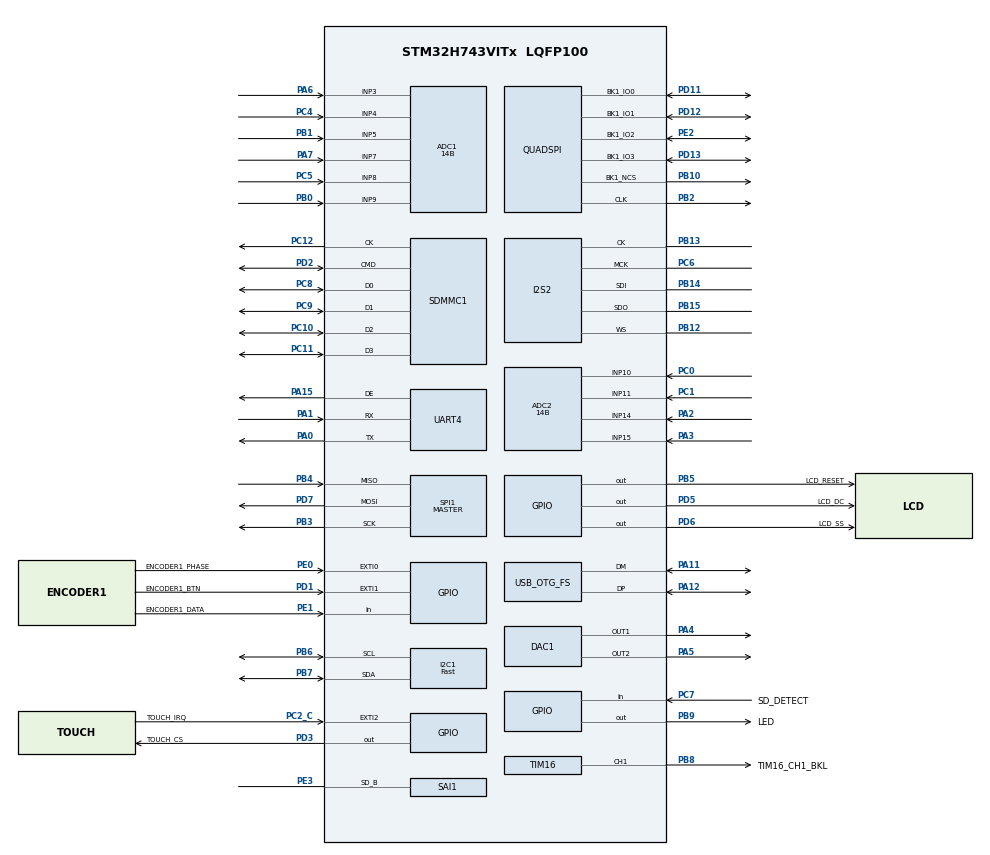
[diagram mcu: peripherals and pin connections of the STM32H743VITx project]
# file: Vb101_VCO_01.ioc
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ADC1.Channel-1\#ChannelRegularConversion=ADC_CHANNEL_3
ADC1.Channel-2\#ChannelRegularConversion=ADC_CHANNEL_4
ADC1.Channel-3\#ChannelRegularConversion=ADC_CHANNEL_5
ADC1.Channel-4\#ChannelRegularConversion=ADC_CHANNEL_7
ADC1.Channel-5\#ChannelRegularConversion=ADC_CHANNEL_8
ADC1.Channel-6\#ChannelRegularConversion=ADC_CHANNEL_9
ADC1.ContinuousConvMode=DISABLE
ADC1.ConversionDataManagement=ADC_CONVERSIONDATA_DMA_CIRCULAR
ADC1.EOCSelection=ADC_EOC_SEQ_CONV
ADC1.ExternalTrigConv=ADC_EXTERNALTRIG_T6_TRGO
ADC1.NbrOfConversion=6
ADC1.NbrOfConversionFlag=1
ADC1.OffsetNumber-1\#ChannelRegularConversion=ADC_OFFSET_NONE
ADC1.OffsetNumber-2\#ChannelRegularConversion=ADC_OFFSET_NONE
ADC1.OffsetNumber-3\#ChannelRegularConversion=ADC_OFFSET_NONE
ADC1.OffsetNumber-4\#ChannelRegularConversion=ADC_OFFSET_NONE
ADC1.OffsetNumber-5\#ChannelRegularConversion=ADC_OFFSET_NONE
ADC1.OffsetNumber-6\#ChannelRegularConversion=ADC_OFFSET_NONE
ADC1.OffsetSignedSaturation-1\#ChannelRegularConversion=DISABLE
ADC1.OffsetSignedSaturation-2\#ChannelRegularConversion=DISABLE
ADC1.OffsetSignedSaturation-3\#ChannelRegularConversion=DISABLE
ADC1.OffsetSignedSaturation-4\#ChannelRegularConversion=DISABLE
ADC1.OffsetSignedSaturation-5\#ChannelRegularConversion=DISABLE
ADC1.OffsetSignedSaturation-6\#ChannelRegularConversion=DISABLE
ADC1.OversamplingMode=ENABLE
ADC1.Rank-1\#ChannelRegularConversion=1
ADC1.Rank-2\#ChannelRegularConversion=2
ADC1.Rank-3\#ChannelRegularConversion=3
ADC1.Rank-4\#ChannelRegularConversion=4
ADC1.Rank-5\#ChannelRegularConversion=5
ADC1.Rank-6\#ChannelRegularConversion=6
ADC1.Ratio=64
ADC1.Resolution=ADC_RESOLUTION_14B
ADC1.RightBitShift=ADC_RIGHTBITSHIFT_6
ADC1.SamplingTime-1\#ChannelRegularConversion=ADC_SAMPLETIME_1CYCLE_5
ADC1.SamplingTime-2\#ChannelRegularConversion=ADC_SAMPLETIME_1CYCLE_5
ADC1.SamplingTime-3\#ChannelRegularConversion=ADC_SAMPLETIME_1CYCLE_5
ADC1.SamplingTime-4\#ChannelRegularConversion=ADC_SAMPLETIME_1CYCLE_5
ADC1.SamplingTime-5\#ChannelRegularConversion=ADC_SAMPLETIME_1CYCLE_5
ADC1.SamplingTime-6\#ChannelRegularConversion=ADC_SAMPLETIME_1CYCLE_5
ADC1.master=1
ADC2.Channel-0\#ChannelRegularConversion=ADC_CHANNEL_10
ADC2.Channel-1\#ChannelRegularConversion=ADC_CHANNEL_11
ADC2.Channel-2\#ChannelRegularConversion=ADC_CHANNEL_14
ADC2.Channel-3\#ChannelRegularConversion=ADC_CHANNEL_15
ADC2.ContinuousConvMode=DISABLE
ADC2.ConversionDataManagement=ADC_CONVERSIONDATA_DMA_CIRCULAR
ADC2.EOCSelection=ADC_EOC_SEQ_CONV
ADC2.ExternalTrigConv=ADC_EXTERNALTRIG_T6_TRGO
ADC2.NbrOfConversion=4
ADC2.NbrOfConversionFlag=1
ADC2.OffsetNumber-0\#ChannelRegularConversion=ADC_OFFSET_NONE
ADC2.OffsetNumber-1\#ChannelRegularConversion=ADC_OFFSET_NONE
ADC2.OffsetNumber-2\#ChannelRegularConversion=ADC_OFFSET_NONE
ADC2.OffsetNumber-3\#ChannelRegularConversion=ADC_OFFSET_NONE
ADC2.OffsetSignedSaturation-0\#ChannelRegularConversion=DISABLE
ADC2.OffsetSignedSaturation-1\#ChannelRegularConversion=DISABLE
ADC2.OffsetSignedSaturation-2\#ChannelRegularConversion=DISABLE
ADC2.OffsetSignedSaturation-3\#ChannelRegularConversion=DISABLE
ADC2.Rank-0\#ChannelRegularConversion=1
ADC2.Rank-1\#ChannelRegularConversion=2
ADC2.Rank-2\#ChannelRegularConversion=3
ADC2.Rank-3\#ChannelRegularConversion=4
ADC2.Resolution=ADC_RESOLUTION_14B
ADC2.SamplingTime-0\#ChannelRegularConversion=ADC_SAMPLETIME_1CYCLE_5
ADC2.SamplingTime-1\#ChannelRegularConversion=ADC_SAMPLETIME_1CYCLE_5
ADC2.SamplingTime-2\#ChannelRegularConversion=ADC_SAMPLETIME_1CYCLE_5
ADC2.SamplingTime-3\#ChannelRegularConversion=ADC_SAMPLETIME_1CYCLE_5
CORTEX_M7.AccessPermission-Cortex_Memory_Protection_Unit_Region0_Settings=MPU_REGION_FULL_ACCESS
CORTEX_M7.AccessPermission_Spec=MPU_REGION_FULL_ACCESS
CORTEX_M7.BaseAddress-Cortex_Memory_Protection_Unit_Region0_Settings=0x30000000
CORTEX_M7.BaseAddress_Spec=0x24040000
CORTEX_M7.CPU_DCache=Disabled
CORTEX_M7.CPU_ICache=Enabled
CORTEX_M7.Enable-Cortex_Memory_Protection_Unit_Region0_Settings=MPU_REGION_ENABLE
CORTEX_M7.Enable_S-Cortex_Memory_Protection_Unit_Region1_Settings_S=__NULL
CORTEX_M7.IsBufferable-Cortex_Memory_Protection_Unit_Region0_Settings=MPU_ACCESS_BUFFERABLE
CORTEX_M7.IsBufferable_Spec=MPU_ACCESS_BUFFERABLE
CORTEX_M7.IsShareable-Cortex_Memory_Protection_Unit_Region0_Settings=MPU_ACCESS_SHAREABLE
CORTEX_M7.MPU_Control=__NULL
CORTEX_M7.Size-Cortex_Memory_Protection_Unit_Region0_Settings=MPU_REGION_SIZE_4KB
CORTEX_M7.Size_Spec=MPU_REGION_SIZE_64KB
CORTEX_M7.default_mode_Activation=1
DAC1.DAC_Channel-DAC_OUT1_ExtAndInt=DAC_CHANNEL_1
DAC1.DAC_Channel-DAC_OUT2_ExtAndInt=DAC_CHANNEL_2
Dma.ADC1.0.Direction=DMA_PERIPH_TO_MEMORY
Dma.ADC1.0.EventEnable=DISABLE
Dma.ADC1.0.FIFOMode=DMA_FIFOMODE_DISABLE
Dma.ADC1.0.Instance=DMA1_Stream0
Dma.ADC1.0.MemDataAlignment=DMA_MDATAALIGN_HALFWORD
Dma.ADC1.0.MemInc=DMA_MINC_ENABLE
Dma.ADC1.0.Mode=DMA_CIRCULAR
Dma.ADC1.0.PeriphDataAlignment=DMA_PDATAALIGN_HALFWORD
Dma.ADC1.0.PeriphInc=DMA_PINC_DISABLE
Dma.ADC1.0.Polarity=HAL_DMAMUX_REQ_GEN_RISING
Dma.ADC1.0.Priority=DMA_PRIORITY_LOW
Dma.ADC1.0.RequestNumber=1
Dma.ADC1.0.SignalID=NONE
Dma.ADC1.0.SyncEnable=DISABLE
Dma.ADC1.0.SyncPolarity=HAL_DMAMUX_SYNC_NO_EVENT
Dma.ADC1.0.SyncRequestNumber=1
Dma.ADC1.0.SyncSignalID=NONE
Dma.ADC2.1.Direction=DMA_PERIPH_TO_MEMORY
Dma.ADC2.1.EventEnable=DISABLE
Dma.ADC2.1.FIFOMode=DMA_FIFOMODE_DISABLE
Dma.ADC2.1.Instance=DMA1_Stream1
Dma.ADC2.1.MemDataAlignment=DMA_MDATAALIGN_HALFWORD
Dma.ADC2.1.MemInc=DMA_MINC_ENABLE
Dma.ADC2.1.Mode=DMA_CIRCULAR
Dma.ADC2.1.PeriphDataAlignment=DMA_PDATAALIGN_HALFWORD
Dma.ADC2.1.PeriphInc=DMA_PINC_DISABLE
Dma.ADC2.1.Polarity=HAL_DMAMUX_REQ_GEN_RISING
Dma.ADC2.1.Priority=DMA_PRIORITY_LOW
Dma.ADC2.1.RequestNumber=1
Dma.ADC2.1.SignalID=NONE
Dma.ADC2.1.SyncEnable=DISABLE
Dma.ADC2.1.SyncPolarity=HAL_DMAMUX_SYNC_NO_EVENT
Dma.ADC2.1.SyncRequestNumber=1
Dma.ADC2.1.SyncSignalID=NONE
Dma.Request0=ADC1
Dma.Request1=ADC2
Dma.Request2=SPI2_TX
Dma.Request3=SPI2_RX
Dma.Request4=SPI1_TX
Dma.SPI1_TX.4.Direction=DMA_MEMORY_TO_PERIPH
Dma.SPI1_TX.4.EventEnable=DISABLE
Dma.SPI1_TX.4.FIFOMode=DMA_FIFOMODE_DISABLE
Dma.SPI1_TX.4.Instance=DMA1_Stream4
Dma.SPI1_TX.4.MemDataAlignment=DMA_MDATAALIGN_BYTE
Dma.SPI1_TX.4.MemInc=DMA_MINC_ENABLE
Dma.SPI1_TX.4.Mode=DMA_NORMAL
Dma.SPI1_TX.4.PeriphDataAlignment=DMA_PDATAALIGN_BYTE
Dma.SPI1_TX.4.PeriphInc=DMA_PINC_DISABLE
Dma.SPI1_TX.4.Polarity=HAL_DMAMUX_REQ_GEN_RISING
Dma.SPI1_TX.4.Priority=DMA_PRIORITY_LOW
Dma.SPI1_TX.4.RequestNumber=1
Dma.SPI1_TX.4.SignalID=NONE
Dma.SPI1_TX.4.SyncEnable=DISABLE
Dma.SPI1_TX.4.SyncPolarity=HAL_DMAMUX_SYNC_NO_EVENT
Dma.SPI1_TX.4.SyncRequestNumber=1
Dma.SPI1_TX.4.SyncSignalID=NONE
Dma.SPI2_RX.3.Direction=DMA_PERIPH_TO_MEMORY
Dma.SPI2_RX.3.EventEnable=DISABLE
Dma.SPI2_RX.3.FIFOMode=DMA_FIFOMODE_DISABLE
Dma.SPI2_RX.3.Instance=DMA2_Stream1
Dma.SPI2_RX.3.MemDataAlignment=DMA_MDATAALIGN_HALFWORD
Dma.SPI2_RX.3.MemInc=DMA_MINC_ENABLE
Dma.SPI2_RX.3.Mode=DMA_CIRCULAR
Dma.SPI2_RX.3.PeriphDataAlignment=DMA_PDATAALIGN_HALFWORD
Dma.SPI2_RX.3.PeriphInc=DMA_PINC_DISABLE
Dma.SPI2_RX.3.Polarity=HAL_DMAMUX_REQ_GEN_RISING
Dma.SPI2_RX.3.Priority=DMA_PRIORITY_LOW
Dma.SPI2_RX.3.RequestNumber=1
Dma.SPI2_RX.3.SignalID=NONE
Dma.SPI2_RX.3.SyncEnable=DISABLE
Dma.SPI2_RX.3.SyncPolarity=HAL_DMAMUX_SYNC_NO_EVENT
Dma.SPI2_RX.3.SyncRequestNumber=1
Dma.SPI2_RX.3.SyncSignalID=NONE
Dma.SPI2_TX.2.Direction=DMA_MEMORY_TO_PERIPH
Dma.SPI2_TX.2.EventEnable=DISABLE
Dma.SPI2_TX.2.FIFOMode=DMA_FIFOMODE_DISABLE
Dma.SPI2_TX.2.Instance=DMA2_Stream0
Dma.SPI2_TX.2.MemDataAlignment=DMA_MDATAALIGN_HALFWORD
Dma.SPI2_TX.2.MemInc=DMA_MINC_ENABLE
Dma.SPI2_TX.2.Mode=DMA_CIRCULAR
Dma.SPI2_TX.2.PeriphDataAlignment=DMA_PDATAALIGN_HALFWORD
Dma.SPI2_TX.2.PeriphInc=DMA_PINC_DISABLE
Dma.SPI2_TX.2.Polarity=HAL_DMAMUX_REQ_GEN_RISING
Dma.SPI2_TX.2.Priority=DMA_PRIORITY_LOW
Dma.SPI2_TX.2.RequestNumber=1
Dma.SPI2_TX.2.SignalID=NONE
Dma.SPI2_TX.2.SyncEnable=DISABLE
Dma.SPI2_TX.2.SyncPolarity=HAL_DMAMUX_SYNC_NO_EVENT
Dma.SPI2_TX.2.SyncRequestNumber=1
Dma.SPI2_TX.2.SyncSignalID=NONE
FATFS.BSP.number=1
FATFS._FS_EXFAT=1
FATFS._FS_TINY=1
FATFS._USE_LFN=1
FATFS0.BSP.STBoard=false
FATFS0.BSP.api=Unknown
FATFS0.BSP.instance=PC7
FATFS0.BSP.ip=GPIO
FATFS0.BSP.mode=Input
FATFS0.BSP.name=Detect_SDIO
FATFS0.BSP.solution=PC7
I2C1.I2C_Speed_Mode=I2C_Fast
I2C1.Timing=0x0010061A
I2S2.AudioFreq=I2S_AUDIOFREQ_48K
I2S2.DataFormat=I2S_DATAFORMAT_16B_EXTENDED
I2S2.ErrorAudioFreq=0.0 %
I2S2.Instance=SPI$Index
I2S2.RealAudioFreq=48.0 KHz
Mcu.Family=STM32H7
Mcu.Name=STM32H743VITx
Mcu.Package=LQFP100
NVIC.DMA1_Stream0_IRQn=true\:0\:0\:false\:false\:true\:false\:true\:true
NVIC.DMA1_Stream1_IRQn=true\:0\:0\:false\:false\:true\:false\:true\:true
NVIC.DMA1_Stream4_IRQn=true\:0\:0\:false\:false\:true\:false\:true\:true
NVIC.DMA2_Stream0_IRQn=true\:0\:0\:false\:false\:true\:false\:true\:true
NVIC.DMA2_Stream1_IRQn=true\:0\:0\:false\:false\:true\:false\:true\:true
NVIC.EXTI0_IRQn=true\:0\:0\:false\:false\:true\:true\:true\:true
NVIC.EXTI1_IRQn=true\:0\:0\:false\:false\:true\:true\:true\:true
NVIC.EXTI2_IRQn=true\:0\:0\:false\:false\:true\:true\:true\:true
NVIC.OTG_FS_IRQn=true\:0\:0\:false\:false\:true\:false\:true\:true
NVIC.PriorityGroup=NVIC_PRIORITYGROUP_4
NVIC.SPI1_IRQn=true\:0\:0\:false\:false\:true\:false\:true\:true
NVIC.TIM6_DAC_IRQn=true\:0\:0\:false\:false\:true\:true\:true\:true
PA0.Mode=Asynchronous
PA0.Signal=UART4_TX
PA1.Mode=Asynchronous
PA1.Signal=UART4_RX
PA11.Mode=Device_Only
PA11.Signal=USB_OTG_FS_DM
PA12.Mode=Device_Only
PA12.Signal=USB_OTG_FS_DP
PA13\ (JTMS/SWDIO).Mode=Serial_Wire
PA13\ (JTMS/SWDIO).Signal=DEBUG_JTMS-SWDIO
PA14\ (JTCK/SWCLK).Mode=Serial_Wire
PA14\ (JTCK/SWCLK).Signal=DEBUG_JTCK-SWCLK
PA15\ (JTDI).Mode=Hardware Flow Control (RS485)
PA15\ (JTDI).Signal=UART4_DE
PA2.Signal=ADCx_INP14
PA3.Signal=ADCx_INP15
PA4.Signal=COMP_DAC11_group
PA5.Signal=COMP_DAC12_group
PA6.Signal=ADCx_INP3
PA7.Signal=ADCx_INP7
PB0.Signal=ADCx_INP9
PB1.Signal=ADCx_INP5
PB10.Mode=Single Bank 1
PB10.Signal=QUADSPI_BK1_NCS
PB12.Mode=Full_Duplex_Master
PB12.Signal=I2S2_WS
PB13.Mode=Full_Duplex_Master
PB13.Signal=I2S2_CK
PB14.Mode=Full_Duplex_Master
PB14.Signal=I2S2_SDI
PB15.Mode=Full_Duplex_Master
PB15.Signal=I2S2_SDO
PB2.Mode=Single Bank 1
PB2.Signal=QUADSPI_CLK
PB3\ (JTDO/TRACESWO).Mode=Full_Duplex_Master
PB3\ (JTDO/TRACESWO).Signal=SPI1_SCK
PB4\ (NJTRST).Mode=Full_Duplex_Master
PB4\ (NJTRST).Signal=SPI1_MISO
PB5.GPIO_Label=LCD_RESET
PB5.Signal=GPIO_Output
PB6.Mode=I2C
PB6.Signal=I2C1_SCL
PB7.Mode=I2C
PB7.Signal=I2C1_SDA
PB8.GPIO_Label=TIM16_CH1_BKL
PB8.Signal=S_TIM16_CH1
PB9.GPIO_Label=LED
PB9.PinState=GPIO_PIN_SET
PB9.Signal=GPIO_Output
PC0.Signal=ADCx_INP10
PC1.Signal=ADCx_INP11
PC10.Mode=SD_4_bits_Wide_bus
PC10.Signal=SDMMC1_D2
PC11.Mode=SD_4_bits_Wide_bus
PC11.Signal=SDMMC1_D3
PC12.Mode=SD_4_bits_Wide_bus
PC12.Signal=SDMMC1_CK
PC2_C.GPIO_Label=TOUCH_IRQ
PC2_C.Signal=GPXTI2
PC4.Signal=ADCx_INP4
PC5.Signal=ADCx_INP8
PC6.Mode=Master_Clock_Activated
PC6.Signal=I2S2_MCK
PC7.GPIO_Label=SD_DETECT
PC7.GPIO_PuPd=GPIO_PULLUP
PC7.Signal=GPIO_Input
PC8.Mode=SD_4_bits_Wide_bus
PC8.Signal=SDMMC1_D0
PC9.Mode=SD_4_bits_Wide_bus
PC9.Signal=SDMMC1_D1
PD1.GPIO_Label=ENCODER1_BTN
PD1.GPIO_ModeDefaultEXTI=GPIO_MODE_IT_FALLING
PD1.GPIO_PuPd=GPIO_PULLUP
PD1.Signal=GPXTI1
PD11.Mode=Single Bank 1
PD11.Signal=QUADSPI_BK1_IO0
PD12.Mode=Single Bank 1
PD12.Signal=QUADSPI_BK1_IO1
PD13.Mode=Single Bank 1
PD13.Signal=QUADSPI_BK1_IO3
PD2.Mode=SD_4_bits_Wide_bus
PD2.Signal=SDMMC1_CMD
PD3.GPIO_Label=TOUCH_CS
PD3.Signal=GPIO_Output
PD5.GPIO_Label=LCD_DC
PD5.Signal=GPIO_Output
PD6.GPIO_Label=LCD_SS
PD6.Signal=GPIO_Output
PD7.Mode=Full_Duplex_Master
PD7.Signal=SPI1_MOSI
PE0.GPIO_Label=ENCODER1_PHASE
PE0.GPIO_ModeDefaultEXTI=GPIO_MODE_IT_FALLING
PE0.GPIO_PuPd=GPIO_PULLUP
PE0.Signal=GPXTI0
PE1.GPIO_Label=ENCODER1_DATA
PE1.GPIO_PuPd=GPIO_PULLUP
PE1.Signal=GPIO_Input
PE2.Mode=Single Bank 1
PE2.Signal=QUADSPI_BK1_IO2
PE3.Mode=SAI_B_SPDIF
PE3.Signal=SAI1_SD_B
PH0-OSC_IN\ (PH0).Mode=HSE-External-Oscillator
PH0-OSC_IN\ (PH0).Signal=RCC_OSC_IN
PH1-OSC_OUT\ (PH1).Mode=HSE-External-Oscillator
PH1-OSC_OUT\ (PH1).Signal=RCC_OSC_OUT
ProjectManager.HeapSize=0x200
ProjectManager.StackSize=0x400
ProjectManager.TargetToolchain=STM32CubeIDE
QUADSPI.ChipSelectHighTime=QSPI_CS_HIGH_TIME_1_CYCLE
QUADSPI.ClockMode=QSPI_CLOCK_MODE_0
QUADSPI.ClockPrescaler=1
QUADSPI.FifoThreshold=1
QUADSPI.FlashSize=23
RCC.ADCCLockSelection=RCC_ADCCLKSOURCE_PLL3
RCC.ADCFreq_Value=6144030.76171875
RCC.APB1Freq_Value=120000000
RCC.APB2Freq_Value=120000000
RCC.APB3Freq_Value=120000000
RCC.APB4Freq_Value=120000000
RCC.CortexFreq_Value=480000000
RCC.D1PPRE=RCC_APB3_DIV2
RCC.D2PPRE1=RCC_APB1_DIV2
RCC.D2PPRE2=RCC_APB2_DIV2
RCC.D3PPRE=RCC_APB4_DIV2
RCC.DIVM1=2
RCC.DIVM2=12
RCC.DIVM3=2
RCC.DIVN1=80
RCC.DIVN2=100
RCC.DIVN3=20
RCC.DIVP2=4
RCC.DIVP3=10
RCC.DIVQ1=4
RCC.DIVQ3=40
RCC.DIVR1=8
RCC.DIVR2=4
RCC.DIVR3=40
RCC.FDCANCLockSelection=RCC_FDCANCLKSOURCE_PLL2
RCC.HCLKFreq_Value=240000000
RCC.HPRE=RCC_HCLK_DIV2
RCC.HSE_VALUE=24000000
RCC.HSIDiv=RCC_PLLSAIDIVR_4
RCC.I2C123CLockSelection=RCC_I2C123CLKSOURCE_HSI
RCC.LPTIM1CLockSelection=RCC_LPTIM1CLKSOURCE_LSI
RCC.PLL2FRACN=0
RCC.PLL3FRACN=3933
RCC.PLLFRACN=0
RCC.PLLSourceVirtual=RCC_PLLSOURCE_HSE
RCC.PWR_Regulator_Voltage_Scale=PWR_REGULATOR_VOLTAGE_SCALE0
RCC.ProductRev=revV
RCC.QSPICLockSelection=RCC_QSPICLKSOURCE_PLL2
RCC.SAI1CLockSelection=RCC_SAI1CLKSOURCE_PLL3
RCC.SDMMC1CLockSelection=RCC_SDMMCCLKSOURCE_PLL2
RCC.SPI123CLockSelection=RCC_SPI123CLKSOURCE_PLL3
RCC.SYSCLKFreq_VALUE=480000000
RCC.SYSCLKSource=RCC_SYSCLKSOURCE_PLLCLK
RCC.USART234578CLockSelection=RCC_USART234578CLKSOURCE_PLL3
RCC.USBCLockSelection=RCC_USBCLKSOURCE_HSI48
RCC.USBFreq_Value=48000000
SAI1.Instance-SAI_B_SPDIF=SAI$Index_Block_B
SAI1.RealAudioFreq-SAI_B_SPDIF=384.001 KHz
SAI1.VirtualMode-SAI_B_SPDIF=VM_SPDIF
SDMMC1.ClockDiv=2
SDMMC1.HardwareFlowControl=SDMMC_HARDWARE_FLOW_CONTROL_ENABLE
SH.ADCx_INP10.0=ADC2_INP10,IN10-Single-Ended
SH.ADCx_INP11.0=ADC2_INP11,IN11-Single-Ended
SH.ADCx_INP14.0=ADC2_INP14,IN14-Single-Ended
SH.ADCx_INP15.0=ADC2_INP15,IN15-Single-Ended
SH.ADCx_INP3.0=ADC1_INP3,IN3-Single-Ended
SH.ADCx_INP4.0=ADC1_INP4,IN4-Single-Ended
SH.ADCx_INP5.0=ADC1_INP5,IN5-Single-Ended
SH.ADCx_INP7.0=ADC1_INP7,IN7-Single-Ended
SH.ADCx_INP8.0=ADC1_INP8,IN8-Single-Ended
SH.ADCx_INP9.0=ADC1_INP9,IN9-Single-Ended
SH.COMP_DAC11_group.0=DAC1_OUT1,DAC_OUT1_ExtAndInt
SH.COMP_DAC12_group.0=DAC1_OUT2,DAC_OUT2_ExtAndInt
SH.S_TIM16_CH1.0=TIM16_CH1,PWM Generation1 CH1
SPI1.BaudRatePrescaler=SPI_BAUDRATEPRESCALER_2
SPI1.CalculateBaudRate=12.288061 MBits/s
SPI1.DataSize=SPI_DATASIZE_8BIT
SPI1.Direction=SPI_DIRECTION_2LINES
SPI1.Mode=SPI_MODE_MASTER
SPI1.VirtualType=VM_MASTER
TIM16.Channel=TIM_CHANNEL_1
TIM16.Period=1000
TIM16.Prescaler=240
TIM16.Pulse=500
TIM6.Period=1000
TIM6.Prescaler=240
TIM6.TIM_MasterOutputTrigger=TIM_TRGO_UPDATE
USB_DEVICE.CLASS_NAME_FS=CDC
USB_DEVICE.VirtualMode-CDC_FS=Cdc
USB_DEVICE.VirtualModeFS=Cdc_FS
USB_OTG_FS.VirtualMode=Device_Only
VP_CRC_VS_CRC.Mode=CRC_Activate
VP_FATFS_VS_SDIO.Mode=SDIO
VP_RNG_VS_RNG.Mode=RNG_Activate
VP_TIM16_VS_ClockSourceINT.Mode=Enable_Timer
VP_TIM6_VS_ClockSourceINT.Mode=Enable_Timer
VP_USB_DEVICE_VS_USB_DEVICE_CDC_FS.Mode=CDC_FS
board=custom

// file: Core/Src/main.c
/* USER CODE BEGIN Header */
/**
  ******************************************************************************
  * @file           : main.c
  * @brief          : Main program body
  ******************************************************************************
  * @attention
  *
  * Copyright (c) 2024 STMicroelectronics.
  * All rights reserved.
  *
  * This software is licensed under terms that can be found in the LICENSE file
  * in the root directory of this software component.
  * If no LICENSE file comes with this software, it is provided AS-IS.
  *
  ******************************************************************************
  */
/* USER CODE END Header */
#include "main.h"
#include "fatfs.h"
#include "usb_device.h"

ADC_HandleTypeDef hadc1;
ADC_HandleTypeDef hadc2;
DMA_HandleTypeDef hdma_adc1;
DMA_HandleTypeDef hdma_adc2;

CRC_HandleTypeDef hcrc;

DAC_HandleTypeDef hdac1;

I2C_HandleTypeDef hi2c1;

I2S_HandleTypeDef hi2s2;
DMA_HandleTypeDef hdma_spi2_tx;
DMA_HandleTypeDef hdma_spi2_rx;

QSPI_HandleTypeDef hqspi;

RNG_HandleTypeDef hrng;

SAI_HandleTypeDef hsai_BlockB1;

SD_HandleTypeDef hsd1;

SPI_HandleTypeDef hspi1;
DMA_HandleTypeDef hdma_spi1_tx;

TIM_HandleTypeDef htim6;
TIM_HandleTypeDef htim16;

UART_HandleTypeDef huart4;

void SystemClock_Config(void);
void PeriphCommonClock_Config(void);
static void MX_GPIO_Init(void);
static void MX_DMA_Init(void);
static void MX_UART4_Init(void);
static void MX_CRC_Init(void);
static void MX_QUADSPI_Init(void);
static void MX_SDMMC1_SD_Init(void);
static void MX_I2C1_Init(void);
static void MX_I2S2_Init(void);
static void MX_TIM16_Init(void);
static void MX_ADC1_Init(void);
static void MX_ADC2_Init(void);
static void MX_DAC1_Init(void);
static void MX_SAI1_Init(void);
static void MX_SPI1_Init(void);
static void MX_TIM6_Init(void);
static void MX_RNG_Init(void);

int main(void)
{
/* Enable the CPU Cache */

  /* Enable I-Cache---------------------------------------------------------*/
  SCB_EnableICache();

  /* MCU Configuration--------------------------------------------------------*/

  /* Reset of all peripherals, Initializes the Flash interface and the Systick. */
  HAL_Init();

  /* Configure the system clock */
  SystemClock_Config();

/* Configure the peripherals common clocks */
  PeriphCommonClock_Config();

  /* USER CODE BEGIN SysInit */
  A_init_mem();

  /* USER CODE END SysInit */

  /* Initialize all configured peripherals */
  MX_GPIO_Init();
  MX_DMA_Init();
  MX_UART4_Init();
  MX_CRC_Init();
  MX_QUADSPI_Init();
  MX_SDMMC1_SD_Init();
  MX_FATFS_Init();
  MX_I2C1_Init();
  MX_I2S2_Init();
  MX_TIM16_Init();
  MX_ADC1_Init();
  MX_ADC2_Init();
  MX_DAC1_Init();
  MX_SAI1_Init();
  MX_SPI1_Init();
  MX_TIM6_Init();
  MX_RNG_Init();
  MX_USB_DEVICE_Init();
  /* USER CODE BEGIN 2 */
  A_start();

  /* USER CODE END 2 */

  /* Infinite loop */
  while (1)
  {

  }
}

void SystemClock_Config(void)
{
  RCC_OscInitTypeDef RCC_OscInitStruct = {0};
  RCC_ClkInitTypeDef RCC_ClkInitStruct = {0};

  /** Supply configuration update enable
  */
  HAL_PWREx_ConfigSupply(PWR_LDO_SUPPLY);

  /** Configure the main internal regulator output voltage
  */
  __HAL_PWR_VOLTAGESCALING_CONFIG(PWR_REGULATOR_VOLTAGE_SCALE1);

  while(!__HAL_PWR_GET_FLAG(PWR_FLAG_VOSRDY)) {}

  __HAL_RCC_SYSCFG_CLK_ENABLE();
  __HAL_PWR_VOLTAGESCALING_CONFIG(PWR_REGULATOR_VOLTAGE_SCALE0);

  while(!__HAL_PWR_GET_FLAG(PWR_FLAG_VOSRDY)) {}

  /** Initializes the RCC Oscillators according to the specified parameters
  * in the RCC_OscInitTypeDef structure.
  */
  RCC_OscInitStruct.OscillatorType = RCC_OSCILLATORTYPE_HSI48|RCC_OSCILLATORTYPE_HSI
                              |RCC_OSCILLATORTYPE_HSE;
  RCC_OscInitStruct.HSEState = RCC_HSE_ON;
  RCC_OscInitStruct.HSIState = RCC_HSI_DIV4;
  RCC_OscInitStruct.HSICalibrationValue = RCC_HSICALIBRATION_DEFAULT;
  RCC_OscInitStruct.HSI48State = RCC_HSI48_ON;
  RCC_OscInitStruct.PLL.PLLState = RCC_PLL_ON;
  RCC_OscInitStruct.PLL.PLLSource = RCC_PLLSOURCE_HSE;
  RCC_OscInitStruct.PLL.PLLM = 2;
  RCC_OscInitStruct.PLL.PLLN = 80;
  RCC_OscInitStruct.PLL.PLLP = 2;
  RCC_OscInitStruct.PLL.PLLQ = 4;
  RCC_OscInitStruct.PLL.PLLR = 8;
  RCC_OscInitStruct.PLL.PLLRGE = RCC_PLL1VCIRANGE_3;
  RCC_OscInitStruct.PLL.PLLVCOSEL = RCC_PLL1VCOWIDE;
  RCC_OscInitStruct.PLL.PLLFRACN = 0;
  if (HAL_RCC_OscConfig(&RCC_OscInitStruct) != HAL_OK)
  {
    Error_Handler();
  }

  /** Initializes the CPU, AHB and APB buses clocks
  */
  RCC_ClkInitStruct.ClockType = RCC_CLOCKTYPE_HCLK|RCC_CLOCKTYPE_SYSCLK
                              |RCC_CLOCKTYPE_PCLK1|RCC_CLOCKTYPE_PCLK2
                              |RCC_CLOCKTYPE_D3PCLK1|RCC_CLOCKTYPE_D1PCLK1;
  RCC_ClkInitStruct.SYSCLKSource = RCC_SYSCLKSOURCE_PLLCLK;
  RCC_ClkInitStruct.SYSCLKDivider = RCC_SYSCLK_DIV1;
  RCC_ClkInitStruct.AHBCLKDivider = RCC_HCLK_DIV2;
  RCC_ClkInitStruct.APB3CLKDivider = RCC_APB3_DIV2;
  RCC_ClkInitStruct.APB1CLKDivider = RCC_APB1_DIV2;
  RCC_ClkInitStruct.APB2CLKDivider = RCC_APB2_DIV2;
  RCC_ClkInitStruct.APB4CLKDivider = RCC_APB4_DIV2;

  if (HAL_RCC_ClockConfig(&RCC_ClkInitStruct, FLASH_LATENCY_4) != HAL_OK)
  {
    Error_Handler();
  }
}

void PeriphCommonClock_Config(void)
{
  RCC_PeriphCLKInitTypeDef PeriphClkInitStruct = {0};

  /** Initializes the peripherals clock
  */
  PeriphClkInitStruct.PeriphClockSelection = RCC_PERIPHCLK_QSPI|RCC_PERIPHCLK_ADC
                              |RCC_PERIPHCLK_SDMMC|RCC_PERIPHCLK_SAI1
                              |RCC_PERIPHCLK_SPI2|RCC_PERIPHCLK_SPI1
                              |RCC_PERIPHCLK_UART4;
  PeriphClkInitStruct.PLL2.PLL2M = 12;
  PeriphClkInitStruct.PLL2.PLL2N = 100;
  PeriphClkInitStruct.PLL2.PLL2P = 4;
  PeriphClkInitStruct.PLL2.PLL2Q = 2;
  PeriphClkInitStruct.PLL2.PLL2R = 4;
  PeriphClkInitStruct.PLL2.PLL2RGE = RCC_PLL2VCIRANGE_1;
  PeriphClkInitStruct.PLL2.PLL2VCOSEL = RCC_PLL2VCOWIDE;
  PeriphClkInitStruct.PLL2.PLL2FRACN = 0;
  PeriphClkInitStruct.PLL3.PLL3M = 2;
  PeriphClkInitStruct.PLL3.PLL3N = 20;
  PeriphClkInitStruct.PLL3.PLL3P = 10;
  PeriphClkInitStruct.PLL3.PLL3Q = 40;
  PeriphClkInitStruct.PLL3.PLL3R = 40;
  PeriphClkInitStruct.PLL3.PLL3RGE = RCC_PLL3VCIRANGE_3;
  PeriphClkInitStruct.PLL3.PLL3VCOSEL = RCC_PLL3VCOWIDE;
  PeriphClkInitStruct.PLL3.PLL3FRACN = 3933;
  PeriphClkInitStruct.QspiClockSelection = RCC_QSPICLKSOURCE_PLL2;
  PeriphClkInitStruct.SdmmcClockSelection = RCC_SDMMCCLKSOURCE_PLL2;
  PeriphClkInitStruct.Sai1ClockSelection = RCC_SAI1CLKSOURCE_PLL3;
  PeriphClkInitStruct.Spi123ClockSelection = RCC_SPI123CLKSOURCE_PLL3;
  PeriphClkInitStruct.Usart234578ClockSelection = RCC_USART234578CLKSOURCE_PLL3;
  PeriphClkInitStruct.AdcClockSelection = RCC_ADCCLKSOURCE_PLL3;
  if (HAL_RCCEx_PeriphCLKConfig(&PeriphClkInitStruct) != HAL_OK)
  {
    Error_Handler();
  }
}

static void MX_ADC1_Init(void)
{

  ADC_MultiModeTypeDef multimode = {0};
  ADC_ChannelConfTypeDef sConfig = {0};

  /** Common config
  */
  hadc1.Instance = ADC1;
  hadc1.Init.ClockPrescaler = ADC_CLOCK_ASYNC_DIV1;
  hadc1.Init.Resolution = ADC_RESOLUTION_14B;
  hadc1.Init.ScanConvMode = ADC_SCAN_ENABLE;
  hadc1.Init.EOCSelection = ADC_EOC_SEQ_CONV;
  hadc1.Init.LowPowerAutoWait = DISABLE;
  hadc1.Init.ContinuousConvMode = DISABLE;
  hadc1.Init.NbrOfConversion = 6;
  hadc1.Init.DiscontinuousConvMode = DISABLE;
  hadc1.Init.ExternalTrigConv = ADC_EXTERNALTRIG_T6_TRGO;
  hadc1.Init.ExternalTrigConvEdge = ADC_EXTERNALTRIGCONVEDGE_RISING;
  hadc1.Init.ConversionDataManagement = ADC_CONVERSIONDATA_DMA_CIRCULAR;
  hadc1.Init.Overrun = ADC_OVR_DATA_PRESERVED;
  hadc1.Init.LeftBitShift = ADC_LEFTBITSHIFT_NONE;
  hadc1.Init.OversamplingMode = ENABLE;
  hadc1.Init.Oversampling.Ratio = 64;
  hadc1.Init.Oversampling.RightBitShift = ADC_RIGHTBITSHIFT_6;
  hadc1.Init.Oversampling.TriggeredMode = ADC_TRIGGEREDMODE_SINGLE_TRIGGER;
  hadc1.Init.Oversampling.OversamplingStopReset = ADC_REGOVERSAMPLING_CONTINUED_MODE;
  if (HAL_ADC_Init(&hadc1) != HAL_OK)
  {
    Error_Handler();
  }

  /** Configure the ADC multi-mode
  */
  multimode.Mode = ADC_MODE_INDEPENDENT;
  if (HAL_ADCEx_MultiModeConfigChannel(&hadc1, &multimode) != HAL_OK)
  {
    Error_Handler();
  }

  /** Configure Regular Channel
  */
  sConfig.Channel = ADC_CHANNEL_3;
  sConfig.Rank = ADC_REGULAR_RANK_1;
  sConfig.SamplingTime = ADC_SAMPLETIME_1CYCLE_5;
  sConfig.SingleDiff = ADC_SINGLE_ENDED;
  sConfig.OffsetNumber = ADC_OFFSET_NONE;
  sConfig.Offset = 0;
  sConfig.OffsetSignedSaturation = DISABLE;
  if (HAL_ADC_ConfigChannel(&hadc1, &sConfig) != HAL_OK)
  {
    Error_Handler();
  }

  /** Configure Regular Channel
  */
  sConfig.Channel = ADC_CHANNEL_4;
  sConfig.Rank = ADC_REGULAR_RANK_2;
  if (HAL_ADC_ConfigChannel(&hadc1, &sConfig) != HAL_OK)
  {
    Error_Handler();
  }

  /** Configure Regular Channel
  */
  sConfig.Channel = ADC_CHANNEL_5;
  sConfig.Rank = ADC_REGULAR_RANK_3;
  if (HAL_ADC_ConfigChannel(&hadc1, &sConfig) != HAL_OK)
  {
    Error_Handler();
  }

  /** Configure Regular Channel
  */
  sConfig.Channel = ADC_CHANNEL_7;
  sConfig.Rank = ADC_REGULAR_RANK_4;
  if (HAL_ADC_ConfigChannel(&hadc1, &sConfig) != HAL_OK)
  {
    Error_Handler();
  }

  /** Configure Regular Channel
  */
  sConfig.Channel = ADC_CHANNEL_8;
  sConfig.Rank = ADC_REGULAR_RANK_5;
  if (HAL_ADC_ConfigChannel(&hadc1, &sConfig) != HAL_OK)
  {
    Error_Handler();
  }

  /** Configure Regular Channel
  */
  sConfig.Channel = ADC_CHANNEL_9;
  sConfig.Rank = ADC_REGULAR_RANK_6;
  if (HAL_ADC_ConfigChannel(&hadc1, &sConfig) != HAL_OK)
  {
    Error_Handler();
  }

}

static void MX_ADC2_Init(void)
{

  ADC_ChannelConfTypeDef sConfig = {0};

  /** Common config
  */
  hadc2.Instance = ADC2;
  hadc2.Init.ClockPrescaler = ADC_CLOCK_ASYNC_DIV1;
  hadc2.Init.Resolution = ADC_RESOLUTION_14B;
  hadc2.Init.ScanConvMode = ADC_SCAN_ENABLE;
  hadc2.Init.EOCSelection = ADC_EOC_SEQ_CONV;
  hadc2.Init.LowPowerAutoWait = DISABLE;
  hadc2.Init.ContinuousConvMode = DISABLE;
  hadc2.Init.NbrOfConversion = 4;
  hadc2.Init.DiscontinuousConvMode = DISABLE;
  hadc2.Init.ExternalTrigConv = ADC_EXTERNALTRIG_T6_TRGO;
  hadc2.Init.ExternalTrigConvEdge = ADC_EXTERNALTRIGCONVEDGE_RISING;
  hadc2.Init.ConversionDataManagement = ADC_CONVERSIONDATA_DMA_CIRCULAR;
  hadc2.Init.Overrun = ADC_OVR_DATA_PRESERVED;
  hadc2.Init.LeftBitShift = ADC_LEFTBITSHIFT_NONE;
  hadc2.Init.OversamplingMode = DISABLE;
  if (HAL_ADC_Init(&hadc2) != HAL_OK)
  {
    Error_Handler();
  }

  /** Configure Regular Channel
  */
  sConfig.Channel = ADC_CHANNEL_10;
  sConfig.Rank = ADC_REGULAR_RANK_1;
  sConfig.SamplingTime = ADC_SAMPLETIME_1CYCLE_5;
  sConfig.SingleDiff = ADC_SINGLE_ENDED;
  sConfig.OffsetNumber = ADC_OFFSET_NONE;
  sConfig.Offset = 0;
  sConfig.OffsetSignedSaturation = DISABLE;
  if (HAL_ADC_ConfigChannel(&hadc2, &sConfig) != HAL_OK)
  {
    Error_Handler();
  }

  /** Configure Regular Channel
  */
  sConfig.Channel = ADC_CHANNEL_11;
  sConfig.Rank = ADC_REGULAR_RANK_2;
  if (HAL_ADC_ConfigChannel(&hadc2, &sConfig) != HAL_OK)
  {
    Error_Handler();
  }

  /** Configure Regular Channel
  */
  sConfig.Channel = ADC_CHANNEL_14;
  sConfig.Rank = ADC_REGULAR_RANK_3;
  if (HAL_ADC_ConfigChannel(&hadc2, &sConfig) != HAL_OK)
  {
    Error_Handler();
  }

  /** Configure Regular Channel
  */
  sConfig.Channel = ADC_CHANNEL_15;
  sConfig.Rank = ADC_REGULAR_RANK_4;
  if (HAL_ADC_ConfigChannel(&hadc2, &sConfig) != HAL_OK)
  {
    Error_Handler();
  }

}

static void MX_CRC_Init(void)
{

  hcrc.Instance = CRC;
  hcrc.Init.DefaultPolynomialUse = DEFAULT_POLYNOMIAL_ENABLE;
  hcrc.Init.DefaultInitValueUse = DEFAULT_INIT_VALUE_ENABLE;
  hcrc.Init.InputDataInversionMode = CRC_INPUTDATA_INVERSION_NONE;
  hcrc.Init.OutputDataInversionMode = CRC_OUTPUTDATA_INVERSION_DISABLE;
  hcrc.InputDataFormat = CRC_INPUTDATA_FORMAT_BYTES;
  if (HAL_CRC_Init(&hcrc) != HAL_OK)
  {
    Error_Handler();
  }

}

static void MX_DAC1_Init(void)
{

  DAC_ChannelConfTypeDef sConfig = {0};

  /** DAC Initialization
  */
  hdac1.Instance = DAC1;
  if (HAL_DAC_Init(&hdac1) != HAL_OK)
  {
    Error_Handler();
  }

  /** DAC channel OUT1 config
  */
  sConfig.DAC_SampleAndHold = DAC_SAMPLEANDHOLD_DISABLE;
  sConfig.DAC_Trigger = DAC_TRIGGER_NONE;
  sConfig.DAC_OutputBuffer = DAC_OUTPUTBUFFER_ENABLE;
  sConfig.DAC_ConnectOnChipPeripheral = DAC_CHIPCONNECT_ENABLE;
  sConfig.DAC_UserTrimming = DAC_TRIMMING_FACTORY;
  if (HAL_DAC_ConfigChannel(&hdac1, &sConfig, DAC_CHANNEL_1) != HAL_OK)
  {
    Error_Handler();
  }

  /** DAC channel OUT2 config
  */
  if (HAL_DAC_ConfigChannel(&hdac1, &sConfig, DAC_CHANNEL_2) != HAL_OK)
  {
    Error_Handler();
  }

}

static void MX_I2C1_Init(void)
{

  hi2c1.Instance = I2C1;
  hi2c1.Init.Timing = 0x0010061A;
  hi2c1.Init.OwnAddress1 = 0;
  hi2c1.Init.AddressingMode = I2C_ADDRESSINGMODE_7BIT;
  hi2c1.Init.DualAddressMode = I2C_DUALADDRESS_DISABLE;
  hi2c1.Init.OwnAddress2 = 0;
  hi2c1.Init.OwnAddress2Masks = I2C_OA2_NOMASK;
  hi2c1.Init.GeneralCallMode = I2C_GENERALCALL_DISABLE;
  hi2c1.Init.NoStretchMode = I2C_NOSTRETCH_DISABLE;
  if (HAL_I2C_Init(&hi2c1) != HAL_OK)
  {
    Error_Handler();
  }

  /** Configure Analogue filter
  */
  if (HAL_I2CEx_ConfigAnalogFilter(&hi2c1, I2C_ANALOGFILTER_ENABLE) != HAL_OK)
  {
    Error_Handler();
  }

  /** Configure Digital filter
  */
  if (HAL_I2CEx_ConfigDigitalFilter(&hi2c1, 0) != HAL_OK)
  {
    Error_Handler();
  }

}

static void MX_I2S2_Init(void)
{

  hi2s2.Instance = SPI2;
  hi2s2.Init.Mode = I2S_MODE_MASTER_FULLDUPLEX;
  hi2s2.Init.Standard = I2S_STANDARD_PHILIPS;
  hi2s2.Init.DataFormat = I2S_DATAFORMAT_16B_EXTENDED;
  hi2s2.Init.MCLKOutput = I2S_MCLKOUTPUT_ENABLE;
  hi2s2.Init.AudioFreq = I2S_AUDIOFREQ_48K;
  hi2s2.Init.CPOL = I2S_CPOL_LOW;
  hi2s2.Init.FirstBit = I2S_FIRSTBIT_MSB;
  hi2s2.Init.WSInversion = I2S_WS_INVERSION_DISABLE;
  hi2s2.Init.Data24BitAlignment = I2S_DATA_24BIT_ALIGNMENT_RIGHT;
  hi2s2.Init.MasterKeepIOState = I2S_MASTER_KEEP_IO_STATE_DISABLE;
  if (HAL_I2S_Init(&hi2s2) != HAL_OK)
  {
    Error_Handler();
  }

}

static void MX_QUADSPI_Init(void)
{

  /* QUADSPI parameter configuration*/
  hqspi.Instance = QUADSPI;
  hqspi.Init.ClockPrescaler = 1;
  hqspi.Init.FifoThreshold = 1;
  hqspi.Init.SampleShifting = QSPI_SAMPLE_SHIFTING_NONE;
  hqspi.Init.FlashSize = 23;
  hqspi.Init.ChipSelectHighTime = QSPI_CS_HIGH_TIME_1_CYCLE;
  hqspi.Init.ClockMode = QSPI_CLOCK_MODE_0;
  hqspi.Init.FlashID = QSPI_FLASH_ID_1;
  hqspi.Init.DualFlash = QSPI_DUALFLASH_DISABLE;
  if (HAL_QSPI_Init(&hqspi) != HAL_OK)
  {
    Error_Handler();
  }

}

static void MX_RNG_Init(void)
{

  hrng.Instance = RNG;
  hrng.Init.ClockErrorDetection = RNG_CED_ENABLE;
  if (HAL_RNG_Init(&hrng) != HAL_OK)
  {
    Error_Handler();
  }

}

static void MX_SAI1_Init(void)
{

  hsai_BlockB1.Instance = SAI1_Block_B;
  hsai_BlockB1.Init.Protocol = SAI_SPDIF_PROTOCOL;
  hsai_BlockB1.Init.AudioMode = SAI_MODEMASTER_TX;
  hsai_BlockB1.Init.Synchro = SAI_ASYNCHRONOUS;
  hsai_BlockB1.Init.OutputDrive = SAI_OUTPUTDRIVE_DISABLE;
  hsai_BlockB1.Init.FIFOThreshold = SAI_FIFOTHRESHOLD_EMPTY;
  hsai_BlockB1.Init.AudioFrequency = SAI_AUDIO_FREQUENCY_48K;
  hsai_BlockB1.Init.MonoStereoMode = SAI_STEREOMODE;
  hsai_BlockB1.Init.CompandingMode = SAI_NOCOMPANDING;
  hsai_BlockB1.Init.PdmInit.Activation = DISABLE;
  hsai_BlockB1.Init.PdmInit.MicPairsNbr = 1;
  hsai_BlockB1.Init.PdmInit.ClockEnable = SAI_PDM_CLOCK1_ENABLE;
  if (HAL_SAI_Init(&hsai_BlockB1) != HAL_OK)
  {
    Error_Handler();
  }

}

static void MX_SDMMC1_SD_Init(void)
{

  hsd1.Instance = SDMMC1;
  hsd1.Init.ClockEdge = SDMMC_CLOCK_EDGE_RISING;
  hsd1.Init.ClockPowerSave = SDMMC_CLOCK_POWER_SAVE_DISABLE;
  hsd1.Init.BusWide = SDMMC_BUS_WIDE_4B;
  hsd1.Init.HardwareFlowControl = SDMMC_HARDWARE_FLOW_CONTROL_ENABLE;
  hsd1.Init.ClockDiv = 2;

}

static void MX_SPI1_Init(void)
{

  /* SPI1 parameter configuration*/
  hspi1.Instance = SPI1;
  hspi1.Init.Mode = SPI_MODE_MASTER;
  hspi1.Init.Direction = SPI_DIRECTION_2LINES;
  hspi1.Init.DataSize = SPI_DATASIZE_8BIT;
  hspi1.Init.CLKPolarity = SPI_POLARITY_LOW;
  hspi1.Init.CLKPhase = SPI_PHASE_1EDGE;
  hspi1.Init.NSS = SPI_NSS_SOFT;
  hspi1.Init.BaudRatePrescaler = SPI_BAUDRATEPRESCALER_2;
  hspi1.Init.FirstBit = SPI_FIRSTBIT_MSB;
  hspi1.Init.TIMode = SPI_TIMODE_DISABLE;
  hspi1.Init.CRCCalculation = SPI_CRCCALCULATION_DISABLE;
  hspi1.Init.CRCPolynomial = 0x0;
  hspi1.Init.NSSPMode = SPI_NSS_PULSE_ENABLE;
  hspi1.Init.NSSPolarity = SPI_NSS_POLARITY_LOW;
  hspi1.Init.FifoThreshold = SPI_FIFO_THRESHOLD_01DATA;
  hspi1.Init.TxCRCInitializationPattern = SPI_CRC_INITIALIZATION_ALL_ZERO_PATTERN;
  hspi1.Init.RxCRCInitializationPattern = SPI_CRC_INITIALIZATION_ALL_ZERO_PATTERN;
  hspi1.Init.MasterSSIdleness = SPI_MASTER_SS_IDLENESS_00CYCLE;
  hspi1.Init.MasterInterDataIdleness = SPI_MASTER_INTERDATA_IDLENESS_00CYCLE;
  hspi1.Init.MasterReceiverAutoSusp = SPI_MASTER_RX_AUTOSUSP_DISABLE;
  hspi1.Init.MasterKeepIOState = SPI_MASTER_KEEP_IO_STATE_DISABLE;
  hspi1.Init.IOSwap = SPI_IO_SWAP_DISABLE;
  if (HAL_SPI_Init(&hspi1) != HAL_OK)
  {
    Error_Handler();
  }

}

static void MX_TIM6_Init(void)
{

  TIM_MasterConfigTypeDef sMasterConfig = {0};

  htim6.Instance = TIM6;
  htim6.Init.Prescaler = 240;
  htim6.Init.CounterMode = TIM_COUNTERMODE_UP;
  htim6.Init.Period = 1000;
  htim6.Init.AutoReloadPreload = TIM_AUTORELOAD_PRELOAD_DISABLE;
  if (HAL_TIM_Base_Init(&htim6) != HAL_OK)
  {
    Error_Handler();
  }
  sMasterConfig.MasterOutputTrigger = TIM_TRGO_UPDATE;
  sMasterConfig.MasterSlaveMode = TIM_MASTERSLAVEMODE_DISABLE;
  if (HAL_TIMEx_MasterConfigSynchronization(&htim6, &sMasterConfig) != HAL_OK)
  {
    Error_Handler();
  }

}

static void MX_TIM16_Init(void)
{

  TIM_OC_InitTypeDef sConfigOC = {0};
  TIM_BreakDeadTimeConfigTypeDef sBreakDeadTimeConfig = {0};

  htim16.Instance = TIM16;
  htim16.Init.Prescaler = 240;
  htim16.Init.CounterMode = TIM_COUNTERMODE_UP;
  htim16.Init.Period = 1000;
  htim16.Init.ClockDivision = TIM_CLOCKDIVISION_DIV1;
  htim16.Init.RepetitionCounter = 0;
  htim16.Init.AutoReloadPreload = TIM_AUTORELOAD_PRELOAD_DISABLE;
  if (HAL_TIM_Base_Init(&htim16) != HAL_OK)
  {
    Error_Handler();
  }
  if (HAL_TIM_PWM_Init(&htim16) != HAL_OK)
  {
    Error_Handler();
  }
  sConfigOC.OCMode = TIM_OCMODE_PWM1;
  sConfigOC.Pulse = 500;
  sConfigOC.OCPolarity = TIM_OCPOLARITY_HIGH;
  sConfigOC.OCNPolarity = TIM_OCNPOLARITY_HIGH;
  sConfigOC.OCFastMode = TIM_OCFAST_DISABLE;
  sConfigOC.OCIdleState = TIM_OCIDLESTATE_RESET;
  sConfigOC.OCNIdleState = TIM_OCNIDLESTATE_RESET;
  if (HAL_TIM_PWM_ConfigChannel(&htim16, &sConfigOC, TIM_CHANNEL_1) != HAL_OK)
  {
    Error_Handler();
  }
  sBreakDeadTimeConfig.OffStateRunMode = TIM_OSSR_DISABLE;
  sBreakDeadTimeConfig.OffStateIDLEMode = TIM_OSSI_DISABLE;
  sBreakDeadTimeConfig.LockLevel = TIM_LOCKLEVEL_OFF;
  sBreakDeadTimeConfig.DeadTime = 0;
  sBreakDeadTimeConfig.BreakState = TIM_BREAK_DISABLE;
  sBreakDeadTimeConfig.BreakPolarity = TIM_BREAKPOLARITY_HIGH;
  sBreakDeadTimeConfig.BreakFilter = 0;
  sBreakDeadTimeConfig.AutomaticOutput = TIM_AUTOMATICOUTPUT_DISABLE;
  if (HAL_TIMEx_ConfigBreakDeadTime(&htim16, &sBreakDeadTimeConfig) != HAL_OK)
  {
    Error_Handler();
  }
  HAL_TIM_MspPostInit(&htim16);

}

static void MX_UART4_Init(void)
{

  huart4.Instance = UART4;
  huart4.Init.BaudRate = 115200;
  huart4.Init.WordLength = UART_WORDLENGTH_8B;
  huart4.Init.StopBits = UART_STOPBITS_1;
  huart4.Init.Parity = UART_PARITY_NONE;
  huart4.Init.Mode = UART_MODE_TX_RX;
  huart4.Init.HwFlowCtl = UART_HWCONTROL_NONE;
  huart4.Init.OverSampling = UART_OVERSAMPLING_16;
  huart4.Init.OneBitSampling = UART_ONE_BIT_SAMPLE_DISABLE;
  huart4.Init.ClockPrescaler = UART_PRESCALER_DIV1;
  huart4.AdvancedInit.AdvFeatureInit = UART_ADVFEATURE_NO_INIT;
  if (HAL_RS485Ex_Init(&huart4, UART_DE_POLARITY_HIGH, 0, 0) != HAL_OK)
  {
    Error_Handler();
  }
  if (HAL_UARTEx_SetTxFifoThreshold(&huart4, UART_TXFIFO_THRESHOLD_1_8) != HAL_OK)
  {
    Error_Handler();
  }
  if (HAL_UARTEx_SetRxFifoThreshold(&huart4, UART_RXFIFO_THRESHOLD_1_8) != HAL_OK)
  {
    Error_Handler();
  }
  if (HAL_UARTEx_DisableFifoMode(&huart4) != HAL_OK)
  {
    Error_Handler();
  }

}

static void MX_DMA_Init(void)
{

  /* DMA controller clock enable */
  __HAL_RCC_DMA1_CLK_ENABLE();
  __HAL_RCC_DMA2_CLK_ENABLE();

  /* DMA interrupt init */
  /* DMA1_Stream0_IRQn interrupt configuration */
  HAL_NVIC_SetPriority(DMA1_Stream0_IRQn, 0, 0);
  HAL_NVIC_EnableIRQ(DMA1_Stream0_IRQn);
  /* DMA1_Stream1_IRQn interrupt configuration */
  HAL_NVIC_SetPriority(DMA1_Stream1_IRQn, 0, 0);
  HAL_NVIC_EnableIRQ(DMA1_Stream1_IRQn);
  /* DMA1_Stream4_IRQn interrupt configuration */
  HAL_NVIC_SetPriority(DMA1_Stream4_IRQn, 0, 0);
  HAL_NVIC_EnableIRQ(DMA1_Stream4_IRQn);
  /* DMA2_Stream0_IRQn interrupt configuration */
  HAL_NVIC_SetPriority(DMA2_Stream0_IRQn, 0, 0);
  HAL_NVIC_EnableIRQ(DMA2_Stream0_IRQn);
  /* DMA2_Stream1_IRQn interrupt configuration */
  HAL_NVIC_SetPriority(DMA2_Stream1_IRQn, 0, 0);
  HAL_NVIC_EnableIRQ(DMA2_Stream1_IRQn);

}

static void MX_GPIO_Init(void)
{
  GPIO_InitTypeDef GPIO_InitStruct = {0};

  /* GPIO Ports Clock Enable */
  __HAL_RCC_GPIOE_CLK_ENABLE();
  __HAL_RCC_GPIOH_CLK_ENABLE();
  __HAL_RCC_GPIOC_CLK_ENABLE();
  __HAL_RCC_GPIOA_CLK_ENABLE();
  __HAL_RCC_GPIOB_CLK_ENABLE();
  __HAL_RCC_GPIOD_CLK_ENABLE();

  /*Configure GPIO pin Output Level */
  HAL_GPIO_WritePin(GPIOD, TOUCH_CS_Pin|LCD_DC_Pin|LCD_SS_Pin, GPIO_PIN_RESET);

  /*Configure GPIO pin Output Level */
  HAL_GPIO_WritePin(LCD_RESET_GPIO_Port, LCD_RESET_Pin, GPIO_PIN_RESET);

  /*Configure GPIO pin Output Level */
  HAL_GPIO_WritePin(LED_GPIO_Port, LED_Pin, GPIO_PIN_SET);

  /*Configure GPIO pin : TOUCH_IRQ_Pin */
  GPIO_InitStruct.Pin = TOUCH_IRQ_Pin;
  GPIO_InitStruct.Mode = GPIO_MODE_IT_RISING;
  GPIO_InitStruct.Pull = GPIO_NOPULL;
  HAL_GPIO_Init(TOUCH_IRQ_GPIO_Port, &GPIO_InitStruct);

  /*Configure GPIO pin : SD_DETECT_Pin */
  GPIO_InitStruct.Pin = SD_DETECT_Pin;
  GPIO_InitStruct.Mode = GPIO_MODE_INPUT;
  GPIO_InitStruct.Pull = GPIO_PULLUP;
  HAL_GPIO_Init(SD_DETECT_GPIO_Port, &GPIO_InitStruct);

  /*Configure GPIO pin : ENCODER1_BTN_Pin */
  GPIO_InitStruct.Pin = ENCODER1_BTN_Pin;
  GPIO_InitStruct.Mode = GPIO_MODE_IT_FALLING;
  GPIO_InitStruct.Pull = GPIO_PULLUP;
  HAL_GPIO_Init(ENCODER1_BTN_GPIO_Port, &GPIO_InitStruct);

  /*Configure GPIO pins : TOUCH_CS_Pin LCD_DC_Pin LCD_SS_Pin */
  GPIO_InitStruct.Pin = TOUCH_CS_Pin|LCD_DC_Pin|LCD_SS_Pin;
  GPIO_InitStruct.Mode = GPIO_MODE_OUTPUT_PP;
  GPIO_InitStruct.Pull = GPIO_NOPULL;
  GPIO_InitStruct.Speed = GPIO_SPEED_FREQ_LOW;
  HAL_GPIO_Init(GPIOD, &GPIO_InitStruct);

  /*Configure GPIO pins : LCD_RESET_Pin LED_Pin */
  GPIO_InitStruct.Pin = LCD_RESET_Pin|LED_Pin;
  GPIO_InitStruct.Mode = GPIO_MODE_OUTPUT_PP;
  GPIO_InitStruct.Pull = GPIO_NOPULL;
  GPIO_InitStruct.Speed = GPIO_SPEED_FREQ_LOW;
  HAL_GPIO_Init(GPIOB, &GPIO_InitStruct);

  /*Configure GPIO pin : ENCODER1_PHASE_Pin */
  GPIO_InitStruct.Pin = ENCODER1_PHASE_Pin;
  GPIO_InitStruct.Mode = GPIO_MODE_IT_FALLING;
  GPIO_InitStruct.Pull = GPIO_PULLUP;
  HAL_GPIO_Init(ENCODER1_PHASE_GPIO_Port, &GPIO_InitStruct);

  /*Configure GPIO pin : ENCODER1_DATA_Pin */
  GPIO_InitStruct.Pin = ENCODER1_DATA_Pin;
  GPIO_InitStruct.Mode = GPIO_MODE_INPUT;
  GPIO_InitStruct.Pull = GPIO_PULLUP;
  HAL_GPIO_Init(ENCODER1_DATA_GPIO_Port, &GPIO_InitStruct);

  /* EXTI interrupt init*/
  HAL_NVIC_SetPriority(EXTI0_IRQn, 0, 0);
  HAL_NVIC_EnableIRQ(EXTI0_IRQn);

  HAL_NVIC_SetPriority(EXTI1_IRQn, 0, 0);
  HAL_NVIC_EnableIRQ(EXTI1_IRQn);

  HAL_NVIC_SetPriority(EXTI2_IRQn, 0, 0);
  HAL_NVIC_EnableIRQ(EXTI2_IRQn);

}

void Error_Handler(void)
{
  __disable_irq();
  while (1)
  {
  }
}
